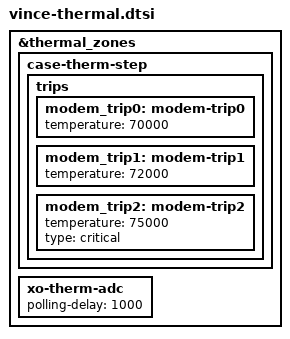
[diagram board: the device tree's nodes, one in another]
&thermal_zones {
	case-therm-step {
		trips {
			modem_trip0: modem-trip0 {
				temperature = <70000>;
			};
			modem_trip1: modem-trip1 {
				temperature = <72000>;
			};
			modem_trip2: modem-trip2 {
				temperature = <75000>;
				type = "critical";
			};
		};
	};

	xo-therm-adc {
		polling-delay = <1000>;
	};
};
